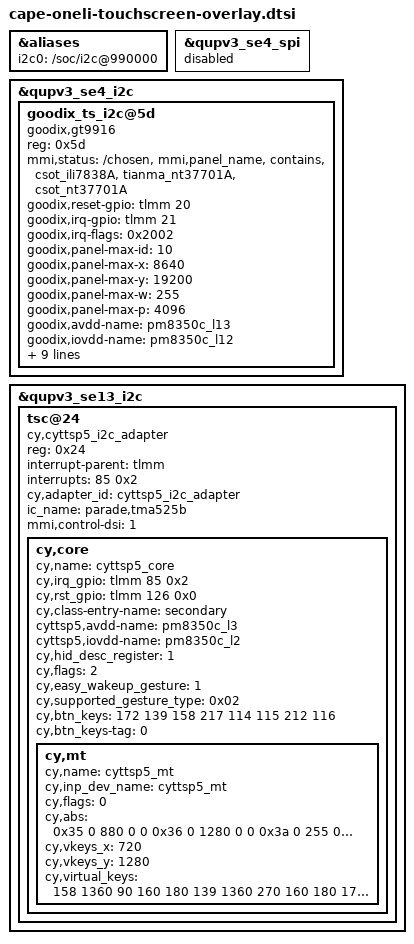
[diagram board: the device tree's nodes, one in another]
/*
 * Copyright (c) 2019, The Linux Foundation. All rights reserved.
 *
 * This program is free software; you can redistribute it and/or modify
 * it under the terms of the GNU General Public License version 2 and
 * only version 2 as published by the Free Software Foundation.
 *
 * This program is distributed in the hope that it will be useful,
 * but WITHOUT ANY WARRANTY; without even the implied warranty of
 * MERCHANTABILITY or FITNESS FOR A PARTICULAR PURPOSE.  See the
 * GNU General Public License for more details.
 */
#include <dt-bindings/clock/qcom,rpmh.h>

&aliases {
	i2c0 = "/soc/i2c@990000";
};

&qupv3_se4_spi {
	status = "disabled";
};

&qupv3_se4_i2c {
	#address-cells = <1>;
	#size-cells = <0>;

	status = "ok";

	goodix_ts_i2c@5d {
		status = "ok";
		compatible = "goodix,gt9916";
		reg = <0x5d>;
		mmi,status = "/chosen","mmi,panel_name","contains","csot_ili7838A","tianma_nt37701A", "csot_nt37701A";
		goodix,reset-gpio = <&tlmm 20 0x0>;
		goodix,irq-gpio = <&tlmm 21 0x2002>;
		goodix,irq-flags = <0x2002>; /* 1:trigger rising, 2:trigger falling;*/
		goodix,panel-max-id = <10>;
		goodix,panel-max-x = <8640>;
		goodix,panel-max-y = <19200>;
		goodix,panel-max-w = <255>;
		goodix,panel-max-p = <4096>;
		goodix,avdd-name = "pm8350c_l13";
		goodix,iovdd-name = "pm8350c_l12";
		goodix,edge-ctrl;
		pinctrl-names = "pmx_ts_active", "pmx_ts_suspend", "pmx_ts_release";
		pinctrl-0 = <&ts_active>;
		pinctrl-1 = <&ts_int_suspend &ts_reset_suspend>;
		pinctrl-2 = <&ts_release>;
		mmi,enable-gestures;
		mmi,power-off-suspend;
		mmi,usb-charger-detection;
		goodix,interpolation-ctrl;
		mmi,supported_gesture_type = <0x06>;
	};
};

&qupv3_se13_i2c {
	#address-cells = <1>;
	#size-cells = <0>;

	status = "ok";

	tsc@24 {
		compatible = "cy,cyttsp5_i2c_adapter";
		reg = <0x24>;
		interrupt-parent = <&tlmm>;
		interrupts = <85 0x2>;
		cy,adapter_id = "cyttsp5_i2c_adapter";
		ic_name = "parade,tma525b";
		mmi,control-dsi = <1>;

		cy,core {
			cy,name = "cyttsp5_core";

			cy,irq_gpio = <&tlmm 85 0x2>;
			cy,rst_gpio = <&tlmm 126 0x0>;
			cy,class-entry-name = "secondary";
			cyttsp5,avdd-name = "pm8350c_l3";
			cyttsp5,iovdd-name = "pm8350c_l2";
			cy,hid_desc_register = <1>;
			/* CY_CORE_FLAG_RESTORE_PARAMETERS */
			cy,flags = <2>;
			/* CY_CORE_EWG_NONE */
			cy,easy_wakeup_gesture = <1>;
			cy,supported_gesture_type = <0x02>;
			cy,btn_keys = <172 /* KEY_HOMEPAGE */
						/* previously was KEY_HOME, new Android versions use KEY_HOMEPAGE */
			               139 /* KEY_MENU */
			               158 /* KEY_BACK */
			               217 /* KEY_SEARCH */
			               114 /* KEY_VOLUMEDOWN */
			               115 /* KEY_VOLUMEUP */
			               212 /* KEY_CAMERA */
			               116>; /* KEY_POWER */
			cy,btn_keys-tag = <0>;

			cy,mt {
				cy,name = "cyttsp5_mt";

				cy,inp_dev_name = "cyttsp5_mt";
				cy,flags = <0>;
				cy,abs =
					/* ABS_MT_POSITION_X, CY_ABS_MIN_X, CY_ABS_MAX_X, 0, 0 */
					<0x35 0 880 0 0
					/* ABS_MT_POSITION_Y, CY_ABS_MIN_Y, CY_ABS_MAX_Y, 0, 0 */
					0x36 0 1280 0 0
					/* ABS_MT_PRESSURE, CY_ABS_MIN_P, CY_ABS_MAX_P, 0, 0 */
					0x3a 0 255 0 0
					/* CY_IGNORE_VALUE, CY_ABS_MIN_W, CY_ABS_MAX_W, 0, 0 */
					0xffff 0 255 0 0
					/* ABS_MT_TRACKING_ID, CY_ABS_MIN_T, CY_ABS_MAX_T, 0, 0 */
					0x39 0 15 0 0
					/* ABS_MT_TOUCH_MAJOR, 0, 255, 0, 0 */
					0x30 0 255 0 0
					/* ABS_MT_TOUCH_MINOR, 0, 255, 0, 0 */
					0x31 0 255 0 0
					/* ABS_MT_ORIENTATION, -127, 127, 0, 0 */
					0x34 0xffffff81 127 0 0
					/* ABS_MT_TOOL_TYPE, 0, MT_TOOL_MAX, 0, 0 */
					0x37 0 1 0 0
					/* ABS_DISTANCE, 0, 255, 0, 0 */
					0x19 0 255 0 0>;

				cy,vkeys_x = <720>;
				cy,vkeys_y = <1280>;

				cy,virtual_keys = /* KeyCode CenterX CenterY Width Height */
					/* KEY_BACK */
					<158 1360 90 160 180
					/* KEY_MENU */
					139 1360 270 160 180
					/* KEY_HOMEPAGE */
					172 1360 450 160 180
					/* KEY SEARCH */
					217 1360 630 160 180>;
			};
		};
	};
};
